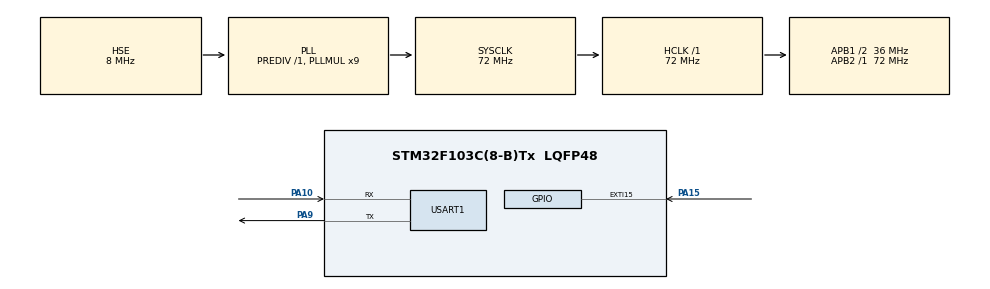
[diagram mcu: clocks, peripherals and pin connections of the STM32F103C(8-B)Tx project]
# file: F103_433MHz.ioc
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Mcu.Family=STM32F1
Mcu.Name=STM32F103C(8-B)Tx
Mcu.Package=LQFP48
NVIC.EXTI15_10_IRQn=true\:1\:0\:true\:false\:true\:true\:true
NVIC.PriorityGroup=NVIC_PRIORITYGROUP_4
PA10.Mode=Asynchronous
PA10.Signal=USART1_RX
PA13.Mode=Serial_Wire
PA13.Signal=SYS_JTMS-SWDIO
PA14.Mode=Serial_Wire
PA14.Signal=SYS_JTCK-SWCLK
PA15.GPIO_ModeDefaultEXTI=GPIO_MODE_IT_RISING_FALLING
PA15.Signal=GPXTI15
PA9.Mode=Asynchronous
PA9.Signal=USART1_TX
PD0-OSC_IN.Mode=HSE-External-Oscillator
PD0-OSC_IN.Signal=RCC_OSC_IN
PD1-OSC_OUT.Mode=HSE-External-Oscillator
PD1-OSC_OUT.Signal=RCC_OSC_OUT
ProjectManager.HeapSize=0x200
ProjectManager.StackSize=0x400
ProjectManager.TargetToolchain=TrueSTUDIO
RCC.AHBFreq_Value=72000000
RCC.APB1CLKDivider=RCC_HCLK_DIV2
RCC.APB1Freq_Value=36000000
RCC.APB1TimFreq_Value=72000000
RCC.APB2Freq_Value=72000000
RCC.APB2TimFreq_Value=72000000
RCC.HCLKFreq_Value=72000000
RCC.PLLMUL=RCC_PLL_MUL9
RCC.PLLSourceVirtual=RCC_PLLSOURCE_HSE
RCC.SYSCLKFreq_VALUE=72000000
RCC.SYSCLKSource=RCC_SYSCLKSOURCE_PLLCLK
RCC.USBFreq_Value=72000000
USART1.VirtualMode=VM_ASYNC
board=custom

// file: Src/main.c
/* USER CODE BEGIN Header */
/**
  ******************************************************************************
  * @file           : main.c
  * @brief          : Main program body
  ******************************************************************************
  * @attention
  *
  * <h2><center>&copy; Copyright (c) 2020 STMicroelectronics.
  * All rights reserved.</center></h2>
  *
  * This software component is licensed by ST under BSD 3-Clause license,
  * the "License"; You may not use this file except in compliance with the
  * License. You may obtain a copy of the License at:
  *                        opensource.org/licenses/BSD-3-Clause
  *
  ******************************************************************************
  */
/* USER CODE END Header */

#include "main.h"

/* USER CODE BEGIN Includes */
#include "rxb6.h"

#include "string.h"
#include "stdio.h"
/* USER CODE END Includes */

UART_HandleTypeDef huart1;

/* USER CODE BEGIN PV */
volatile uint8_t hcs_listening = 0;

extern uint8_t BitArray[SIZE_ARRAY];
extern uint8_t Repeat;
extern uint8_t BatteryLow;
//extern uint8_t Btn2;
//extern uint8_t Btn1;
//extern uint8_t Btn0;
//extern uint8_t Btn3;
extern uint32_t SerialNum;
extern uint32_t Encrypt;
extern uint8_t Button;
/* USER CODE END PV */

void SystemClock_Config(void);
static void MX_GPIO_Init(void);
static void MX_USART1_UART_Init(void);

/* USER CODE BEGIN 0 */
void HAL_GPIO_EXTI_Callback(uint16_t GPIO_Pin)
{
	if(GPIO_Pin == SIGNAL_PIN)
	{
		RX433_Int();
	}
}

/* USER CODE END 0 */

int main(void)
{

  /* MCU Configuration--------------------------------------------------------*/

  /* Reset of all peripherals, Initializes the Flash interface and the Systick. */
  HAL_Init();

  /* Configure the system clock */
  SystemClock_Config();

  /* Initialize all configured peripherals */
  MX_GPIO_Init();
  MX_USART1_UART_Init();
  /* USER CODE BEGIN 2 */
  DWT_Init();

  HAL_UART_Transmit(&huart1, (uint8_t*)"START 433\n", 10, 1000);
  /* USER CODE END 2 */

  /* Infinite loop */
  /* USER CODE BEGIN WHILE */
  while (1)
  {
	  //////////////////////////////// ЧТЕНИЕ ДАННЫХ ////////////////////////////////
	  if(hcs_listening == 1) // пришёл пакет
	  {
		  char sim = ' ';

		  switch(Button)
		  {
			  case 2:
				  sim = 'A';
			  break;

			  case 4:
				  sim = 'B';
			  break;

			  case 8:
				  sim = 'C';
			  break;

			  case 1:
				  sim = 'D';
			  break;

			  default:
			  break;
		  }

		  char str[64] = {0,};
		  snprintf(str, 64, "SN: 0x%lX, Cript: 0x%lX, Butt: %c, LowBat: %d, Rep: %d\n", SerialNum, Encrypt, sim, BatteryLow, Repeat);
		  HAL_UART_Transmit(&huart1, (uint8_t*)str, strlen(str), 1000);

		  memset(BitArray, 0x00, SIZE_ARRAY);
		  SerialNum = 0;
		  Encrypt = 0;
		  BatteryLow = 0;
		  Button = 0;
		  Repeat = 0;

		  hcs_listening = 0;

		  __HAL_GPIO_EXTI_CLEAR_IT(SIGNAL_PIN);  // очищаем бит EXTI_PR
		  NVIC_ClearPendingIRQ(EXTI15_10_IRQn); // очищаем бит NVIC_ICPRx
		  HAL_NVIC_EnableIRQ(EXTI15_10_IRQn);   // включаем прерывания 433
	  }

    /* USER CODE END WHILE */

  }
}

void SystemClock_Config(void)
{
  RCC_OscInitTypeDef RCC_OscInitStruct = {0};
  RCC_ClkInitTypeDef RCC_ClkInitStruct = {0};

  /** Initializes the CPU, AHB and APB busses clocks
  */
  RCC_OscInitStruct.OscillatorType = RCC_OSCILLATORTYPE_HSE;
  RCC_OscInitStruct.HSEState = RCC_HSE_ON;
  RCC_OscInitStruct.HSEPredivValue = RCC_HSE_PREDIV_DIV1;
  RCC_OscInitStruct.HSIState = RCC_HSI_ON;
  RCC_OscInitStruct.PLL.PLLState = RCC_PLL_ON;
  RCC_OscInitStruct.PLL.PLLSource = RCC_PLLSOURCE_HSE;
  RCC_OscInitStruct.PLL.PLLMUL = RCC_PLL_MUL9;
  if (HAL_RCC_OscConfig(&RCC_OscInitStruct) != HAL_OK)
  {
    Error_Handler();
  }
  /** Initializes the CPU, AHB and APB busses clocks
  */
  RCC_ClkInitStruct.ClockType = RCC_CLOCKTYPE_HCLK|RCC_CLOCKTYPE_SYSCLK
                              |RCC_CLOCKTYPE_PCLK1|RCC_CLOCKTYPE_PCLK2;
  RCC_ClkInitStruct.SYSCLKSource = RCC_SYSCLKSOURCE_PLLCLK;
  RCC_ClkInitStruct.AHBCLKDivider = RCC_SYSCLK_DIV1;
  RCC_ClkInitStruct.APB1CLKDivider = RCC_HCLK_DIV2;
  RCC_ClkInitStruct.APB2CLKDivider = RCC_HCLK_DIV1;

  if (HAL_RCC_ClockConfig(&RCC_ClkInitStruct, FLASH_LATENCY_2) != HAL_OK)
  {
    Error_Handler();
  }
}

static void MX_USART1_UART_Init(void)
{

  huart1.Instance = USART1;
  huart1.Init.BaudRate = 115200;
  huart1.Init.WordLength = UART_WORDLENGTH_8B;
  huart1.Init.StopBits = UART_STOPBITS_1;
  huart1.Init.Parity = UART_PARITY_NONE;
  huart1.Init.Mode = UART_MODE_TX_RX;
  huart1.Init.HwFlowCtl = UART_HWCONTROL_NONE;
  huart1.Init.OverSampling = UART_OVERSAMPLING_16;
  if (HAL_UART_Init(&huart1) != HAL_OK)
  {
    Error_Handler();
  }

}

static void MX_GPIO_Init(void)
{
  GPIO_InitTypeDef GPIO_InitStruct = {0};

  /* GPIO Ports Clock Enable */
  __HAL_RCC_GPIOD_CLK_ENABLE();
  __HAL_RCC_GPIOA_CLK_ENABLE();

  /*Configure GPIO pin : PA15 */
  GPIO_InitStruct.Pin = GPIO_PIN_15;
  GPIO_InitStruct.Mode = GPIO_MODE_IT_RISING_FALLING;
  GPIO_InitStruct.Pull = GPIO_NOPULL;
  HAL_GPIO_Init(GPIOA, &GPIO_InitStruct);

  /* EXTI interrupt init*/
  HAL_NVIC_SetPriority(EXTI15_10_IRQn, 1, 0);
  HAL_NVIC_EnableIRQ(EXTI15_10_IRQn);

}

void Error_Handler(void)
{
}

/************************ (C) COPYRIGHT STMicroelectronics *****END OF FILE****/
